# PIC18LF4539 register map
Vendor: Microchip
Architecture 18xxxx. Special function registers and configuration words.
Registers are 8-bit, read-write, no defined reset value unless marked. A register's access mark holds for its fields unless they carry their own. Addresses are absolute, and some are shared; only a register's first bit layout is shown; lines under a group give offsets from that group; [hi:lo] are bit positions; {n}, {i} and the like mark numbered series; 'fields as' and 'values as' point back to an identical list; <NAME> marks a mode.

## Further device data
pins=1: MCLR/Vpp; 2: RA0/AN0; 3: RA1/AN1; 4: RA2/AN2/Vref-; 5: RA3/AN3/Vref+; 6: RA4/T0CKI; 7: RA5/AN4/SS/LVDIN; 8: RE0/RD/AN5; 9: RE1/WR/AN6; 10: RE2/CS/AN7; 11: Vdd; 12: Vss; 13: OSC1/CLKI; 14: OSC2/CLKO/RA6; 15: RC0/T13CKI; 16: PWM2; 17: PWM1; 18: RC3/SCK/SCL; 19: RD0/PSP0; 20: RD1/PSP1; 21: RD2/PSP2; 22: RD3/PSP3; 23: RC4/SDI/SDA; 24: RC5/SDO; 25: RC6/TX/CK; 26: RC7/RX/DT; 27: RD4/PSP4; 28: RD5/PSP5; 29: RD6/PSP6; 30: RD7/PSP7; 31: Vss; 32: Vdd; 33: RB0/INT0; 34: RB1/INT1; 35: RB2/INT2; 36: RB3; 37: RB4; 38: RB5/PGM; 39: RB6/PGC; 40: RB7/PGD

## CONFIG — Configuration words, addresses in ProgramSpace
0x300001 CONFIG1H reset 0x22
  [2:0] OSC — Oscillator
    6=HSPLL (HS oscillator with PLL enabled; clock frequency = (4 x FOSC)); 5=ECIO (EC oscillator w/ OSC2 configured as RA6); 4=EC (EC oscillator w/ OSC2 configured as divide-by-4 clock output); 2=HS (HS oscillator)
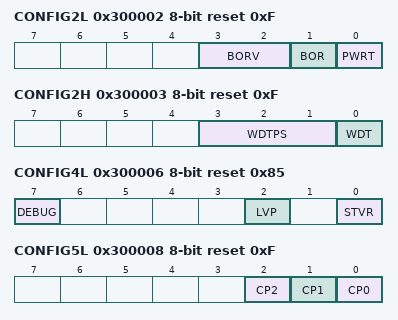
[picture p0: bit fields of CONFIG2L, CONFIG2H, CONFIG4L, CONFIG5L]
0x300002 CONFIG2L reset 0xF
  [3:2] BORV — Brown-out Reset Voltage bits
    3=VBOR set to 2.5V; 2=VBOR set to 2.7V; 1=VBOR set to 4.2V; 0=VBOR set to 4.5V
  [1] BOR — Brown-out Reset Enable bit
    1=ON (Brown-out Reset enabled); 0=OFF (Brown-out Reset disabled)
  [0] PWRT — Power-up Timer Enable bit
    1=OFF (PWRT disabled); 0=ON (PWRT enabled)
0x300003 CONFIG2H reset 0xF
  [3:1] WDTPS — Watchdog Timer Postscale Select bits
    7=1:128; 6=1:64; 5=1:32; 4=1:16; 3=1:8; 2=1:4; 1=1:2; 0=1:1
  [0] WDT — Watchdog Timer Enable bit
    1=ON (WDT enabled); 0=OFF (WDT disabled (control is placed on the SWDTEN bit))
0x300005 CONFIG3H reset 0x1
0x300006 CONFIG4L reset 0x85
  [7] DEBUG — Background Debugger Enable bit
    1=OFF (Background Debugger disabled. RB6 and RB7 configured as general purpose I/O pins.); 0=ON (Background Debugger enabled. RB6 and RB7 are dedicated to In-Circuit Debug.)
  [2] LVP — Low Voltage ICSP Enable bit
    1=ON (Low Voltage ICSP enabled); 0=OFF (Low Voltage ICSP disabled)
  [0] STVR — Stack Full/Underflow Reset Enable bit
    1=ON (Stack Full/Underflow will cause RESET); 0=OFF (Stack Full/Underflow will not cause RESET)
0x300008 CONFIG5L reset 0xF
  [2] CP2 — Code Protection bit
    1=OFF (Block 2 (004000-005FFFh) not code protected); 0=ON (Block 2 (004000-005FFFh) code protected)
  [1] CP1 — Code Protection bit
    1=OFF (Block 1 (002000-003FFFh) not code protected); 0=ON (Block 1 (002000-003FFFh) code protected)
  [0] CP0 — Code Protection bit
    1=OFF (Block 0 (000200-001FFFh) not code protected); 0=ON (Block 0 (000200-001FFFh) code protected)
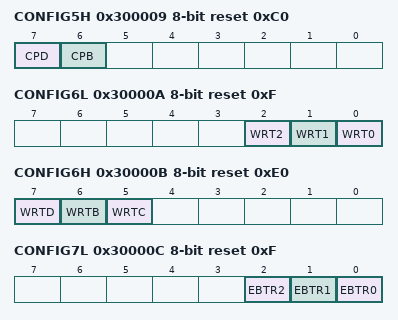
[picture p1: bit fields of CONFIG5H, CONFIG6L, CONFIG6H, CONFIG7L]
0x300009 CONFIG5H reset 0xC0
  [7] CPD — Data EEPROM Code Protection bit
    1=OFF (Data EEPROM not code protected); 0=ON (Data EEPROM code protected)
  [6] CPB — Boot Block Code Protection bit
    1=OFF (Boot block (000000-0001FFh) not code protected); 0=ON (Boot block (000000-0001FFh) code protected)
0x30000A CONFIG6L reset 0xF
  [2] WRT2 — Write Protection bit
    1=OFF (Block 2 (004000-005FFFh) not write protected); 0=ON (Block 2 (004000-005FFFh) write protected)
  [1] WRT1 — Write Protection bit
    1=OFF (Block 1 (002000-003FFFh) not write protected); 0=ON (Block 1 (002000-003FFFh) write protected)
  [0] WRT0 — Write Protection bit
    1=OFF (Block 0 (000200h-001FFFh) not write protected); 0=ON (Block 0 (000200h-001FFFh) write protected)
0x30000B CONFIG6H reset 0xE0
  [7] WRTD — Data EEPROM Write Protection bit
    1=OFF (Data EEPROM not write protected); 0=ON (Data EEPROM write protected)
  [6] WRTB — Boot Block Write Protection bit
    1=OFF (Boot block (000000-0001FFh) not write protected); 0=ON (Boot block (000000-0001FFh) write protected)
  [5] WRTC — Configuration Register Write Protection bit
    1=OFF (Configuration registers (300000-3000FFh) not write protected); 0=ON (Configuration registers (300000-3000FFh) write protected)
0x30000C CONFIG7L reset 0xF
  [2] EBTR2 — Table Read Protection bit
    1=OFF (Block 2 (004000-005FFFh) not protected from Table Reads executed in other blocks); 0=ON (Block 2 (004000-005FFFh) protected from Table Reads executed in other blocks)
  [1] EBTR1 — Table Read Protection bit
    1=OFF (Block 1 (002000-003FFFh) not protected from Table Reads executed in other blocks); 0=ON (Block 1 (002000-003FFFh) protected from Table Reads executed in other blocks)
  [0] EBTR0 — Table Read Protection bit
    1=OFF (Block 0 (000200h-001FFFh) not protected from Table Reads executed in other blocks); 0=ON (Block 0 (000200h-001FFFh) protected from Table Reads executed in other blocks)
0x30000D CONFIG7H reset 0x40
  [6] EBTRB — Boot Block Table Read Protection bit
    1=OFF (Boot block (000000-0001FFh) not protected from Table Reads executed in other blocks); 0=ON (Boot block (000000-0001FFh) protected from Table Reads executed in other blocks)
